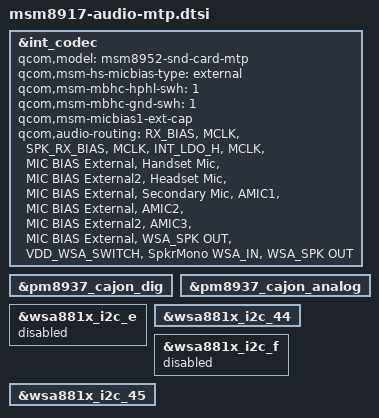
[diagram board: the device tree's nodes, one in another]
/*
 * Copyright (c) 2015, The Linux Foundation. All rights reserved.
 *
 * This program is free software; you can redistribute it and/or modify
 * it under the terms of the GNU General Public License version 2 and
 * only version 2 as published by the Free Software Foundation.
 *
 * This program is distributed in the hope that it will be useful,
 * but WITHOUT ANY WARRANTY; without even the implied warranty of
 * MERCHANTABILITY or FITNESS FOR A PARTICULAR PURPOSE.  See the
 * GNU General Public License for more details.
 */

&int_codec {
	status = "okay";
	qcom,model = "msm8952-snd-card-mtp";
	qcom,msm-hs-micbias-type = "external";

        qcom,msm-mbhc-hphl-swh = <1>;
        qcom,msm-mbhc-gnd-swh = <1>;
        qcom,msm-micbias1-ext-cap;

        qcom,audio-routing =
            "RX_BIAS", "MCLK",
            "SPK_RX_BIAS", "MCLK",
            "INT_LDO_H", "MCLK",
            "MIC BIAS External", "Handset Mic",
            "MIC BIAS External2", "Headset Mic",
            "MIC BIAS External", "Secondary Mic",
            "AMIC1", "MIC BIAS External",
            "AMIC2", "MIC BIAS External2",
            "AMIC3", "MIC BIAS External",
            "WSA_SPK OUT", "VDD_WSA_SWITCH",
            "SpkrMono WSA_IN", "WSA_SPK OUT";
};

&pm8937_cajon_dig {
	status = "okay";
};

&pm8937_cajon_analog {
	status = "okay";
};

&wsa881x_i2c_e {
	status = "disabled";
};

&wsa881x_i2c_44 {
	status = "okay";
};

&wsa881x_i2c_f {
	status = "disabled";
};

&wsa881x_i2c_45 {
	status = "okay";
};
